# IMM100A register map
Vendor: Infineon; File version: 0.8.0 (Reference Manual v0.8.0)
CPU: CM0 r0p0, little endian, no MPU, no FPU, 2 interrupt priority bits
Registers are 32-bit, read-write, reset 0x0 unless marked. A register's access mark holds for its fields unless they carry their own. Offsets are from the block's base; [hi:lo] are bit positions; {n}, {i} and the like mark numbered series; 'fields as' and 'values as' point back to an identical list.

## PORT1
Base 0x40040100
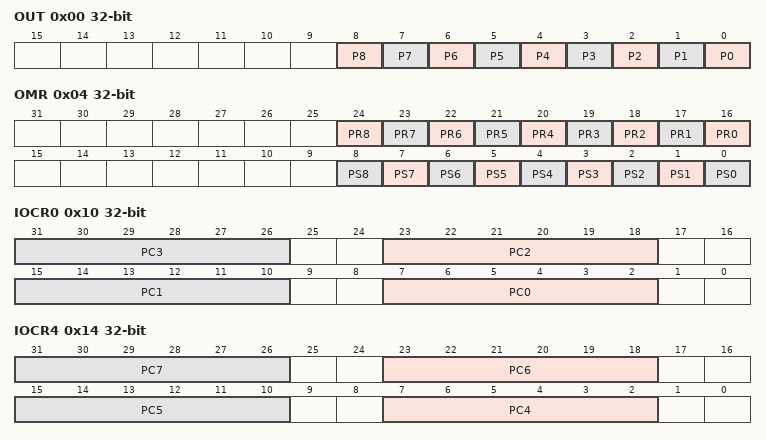
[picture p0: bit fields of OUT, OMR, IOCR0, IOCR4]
0x00 OUT — Port 1 Output Register
  [all] fields
    0=The output level of P1.x is 0; 1=The output level of P1.x is 1
  [8] P8 — Port 1 Output Bit 6
  [7] P7 — Port 1 Output Bit 6
  [n] P{n} (n=0..6) — Port 1 Output Bit {n}
0x04 OMR wo — Port 1 Output Modification Register
  [n+16] PR{n} (n=0..8) — Port 1 Reset Bit {n}
  [n] PS{n} (n=0..8) — Port 1 Set Bit {n}
0x10 IOCR0 — Port 1 Input/Output Control Register 0
  [all] fields
    0=Input - No internal pull device active; 1=Input - Internal pull-down device active; 2=Input - Internal pull-up device active; 3=Input - No internal pull device, Pn_OUTx = input value; 4=Input inverted - No internal pull device active; 5=Input inverted - Internal pull-down device active; 6=Input inverted - Internal pull-up device active; 7=Input inverted - No internal pull device, Pn_OUTx = input value; 32=Output Push-Pull - General-purpose output; {v}=Output Push-Pull - Alternate output function {v-32} (v=33..41); 48=Output Open Drain - General-purpose output; {v}=Output Open Drain - Alternate output function {v-48} (v=49..57)
  [8n+7:8n+2] PC{n} (n=0..3) — Port Control for Port n Pin 0 to 3
0x14 IOCR4 — Port 1 Input/Output Control Register 4
  [all] fields
    values as the fields of IOCR0
  [8n-25:8n-30] PC{n} (n=4..7) — Port Control for Port n Pin 4 to 7
0x18 IOCR8 — Port 1 Input/Output Control Register 8
  [7:2] PC8 — Port Control for Port n Pin 8
    values as the fields of IOCR0
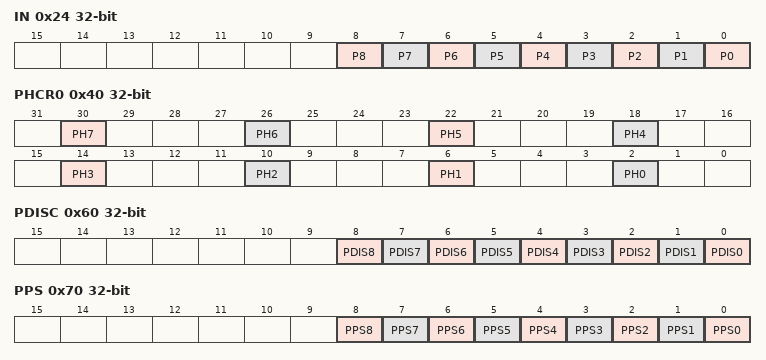
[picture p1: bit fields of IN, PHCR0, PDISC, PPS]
0x24 IN ro (reset mask 0xFFFFF000) — Port 1 Input Register
  [all] fields
    0=The input level of P1.x is 0; 1=The input level of P1.x is 1
  [n] P{n} (n=0..8) — Port 1 Input Bit {n}
0x40 PHCR0 — Port 1 Pad Hysteresis Control Register 0
  [30] PH7 — Pad Hysteresis for P1.7
  [26] PH6 — Pad Hysteresis for P1.6
  [22] PH5 — Pad Hysteresis for P1.5
  [18] PH4 — Pad Hysteresis for P1.4
  [14] PH3 — Pad Hysteresis for P1.3
  [10] PH2 — Pad Hysteresis for P1.2
  [6] PH1 — Pad Hysteresis for P1.1
  [2] PH0 — Pad Hysteresis for P1.0
0x44 PHCR1 — Port 1 Pad Hysteresis Control Register 1
  [2] PH8 — Pad Hysteresis for P1.8
0x60 PDISC ro (reset mask 0xFFFFF000) — Port 1 Pin Function Decision Control Register
  [all] fields
    0=Pad P1.x is enabled; 1=Pad P1.x is disabled
  [n] PDIS{n} (n=0..8) — Pad Disable for Port 1 Pin {n}
0x70 PPS — Port 1 Pin Power Save Register
  [all] fields
    0=Pin Power Save of P1.x is disabled; 1=Pin Power Save of P1.x is enabled
  [n] PPS{n} (n=0..8) — Port 1 Pin Power Save Bit {n}
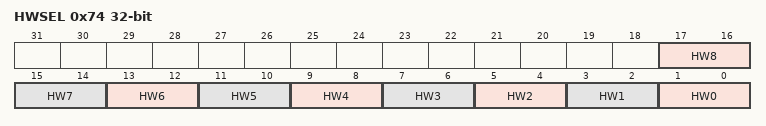
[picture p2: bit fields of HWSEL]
0x74 HWSEL — Port 1 Pin Hardware Select Register
  [all] fields
    0=Software control only; 1=HW0 control path can override the software configuration; 2=HW1 control path can override the software configuration
  [2n+1:2n] HW{n} (n=0..8) — Port 1 Pin Hardware Select Bit {n}

## PORT3
Base 0x40040300
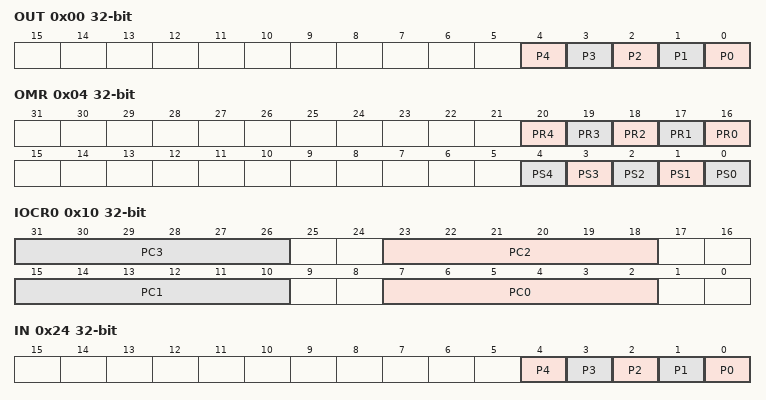
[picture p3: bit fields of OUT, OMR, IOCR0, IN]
0x00 OUT — Port 3 Output Register
  [all] fields
    0=The output level of P3.x is 0; 1=The output level of P3.x is 1
  [n] P{n} (n=0..4) — Port 3 Output Bit {n}
0x04 OMR wo — Port 3 Output Modification Register
  [n+16] PR{n} (n=0..4) — Port 3 Reset Bit {n}
  [n] PS{n} (n=0..4) — Port 3 Set Bit {n}
0x10 IOCR0 — Port 3 Input/Output Control Register 0
  [all] fields
    0=Input - No internal pull device active; 1=Input - Internal pull-down device active; 2=Input - Internal pull-up device active; 3=Input - No internal pull device, Pn_OUTx = input value; 4=Input inverted - No internal pull device active; 5=Input inverted - Internal pull-down device active; 6=Input inverted - Internal pull-up device active; 7=Input inverted - No internal pull device, Pn_OUTx = input value; 32=Output Push-Pull - General-purpose output; {v}=Output Push-Pull - Alternate output function {v-32} (v=33..41); 48=Output Open Drain - General-purpose output; {v}=Output Open Drain - Alternate output function {v-48} (v=49..57)
  [8n+7:8n+2] PC{n} (n=0..3) — Port Control for Port n Pin 0 to 3
0x14 IOCR4 — Port 3 Input/Output Control Register 4
  [7:2] PC4 — Port Control for Port n Pin 4
    values as the fields of IOCR0
0x24 IN ro (reset mask 0xFFFFFF00) — Port 3 Input Register
  [all] fields
    0=The input level of P3.x is 0; 1=The input level of P3.x is 1
  [n] P{n} (n=0..4) — Port 3 Input Bit {n}
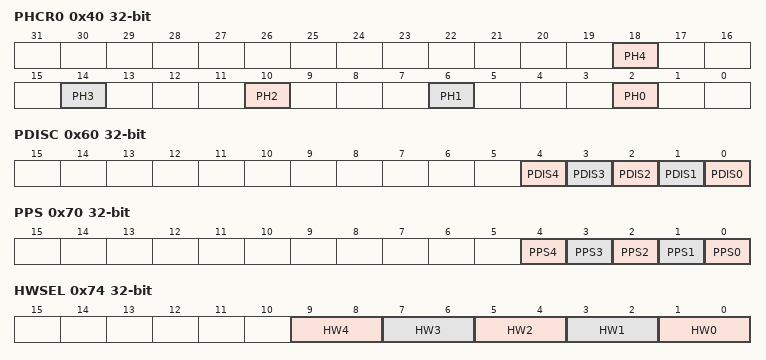
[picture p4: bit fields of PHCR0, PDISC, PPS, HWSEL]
0x40 PHCR0 — Port 3 Pad Hysteresis Control Register 0
  [18] PH4 — Pad Hysteresis for P3.4
  [14] PH3 — Pad Hysteresis for P3.3
  [10] PH2 — Pad Hysteresis for P3.2
  [6] PH1 — Pad Hysteresis for P3.1
  [2] PH0 — Pad Hysteresis for P3.0
0x60 PDISC ro (reset mask 0xFFFFFF00) — Port 3 Pin Function Decision Control Register
  [all] fields
    0=Pad P3.x is enabled; 1=Pad P3.x is disabled
  [n] PDIS{n} (n=0..4) — Pad Disable for Port 3 Pin {n}
0x70 PPS — Port 3 Pin Power Save Register
  [all] fields
    0=Pin Power Save of P3.x is disabled; 1=Pin Power Save of P3.x is enabled
  [n] PPS{n} (n=0..4) — Port 3 Pin Power Save Bit {n}
0x74 HWSEL — Port 3 Pin Hardware Select Register
  [all] fields
    0=Software control only; 1=HW0 control path can override the software configuration; 2=HW1 control path can override the software configuration
  [2n+1:2n] HW{n} (n=0..4) — Port 3 Pin Hardware Select Bit {n}

## PORT4
Base 0x40040400
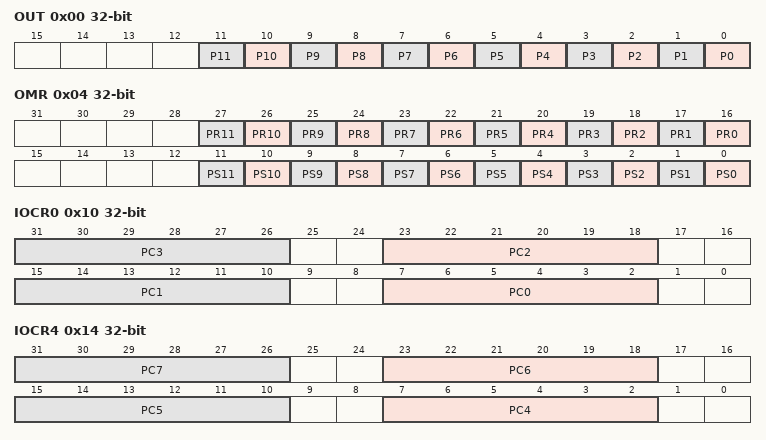
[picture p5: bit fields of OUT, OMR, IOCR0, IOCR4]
0x00 OUT — Port 4 Output Register
  [all] fields
    0=The output level of P4.x is 0; 1=The output level of P4.x is 1
  [n] P{n} (n=0..11) — Port 4 Output Bit {n}
0x04 OMR wo — Port 4 Output Modification Register
  [n+16] PR{n} (n=0..11) — Port 4 Reset Bit {n}
  [n] PS{n} (n=0..11) — Port 4 Set Bit {n}
0x10 IOCR0 — Port 4 Input/Output Control Register 0
  [all] fields
    0=Input - No internal pull device active; 1=Input - Internal pull-down device active; 2=Input - Internal pull-up device active; 3=Input - No internal pull device, Pn_OUTx = input value; 4=Input inverted - No internal pull device active; 5=Input inverted - Internal pull-down device active; 6=Input inverted - Internal pull-up device active; 7=Input inverted - No internal pull device, Pn_OUTx = input value; 32=Output Push-Pull - General-purpose output; {v}=Output Push-Pull - Alternate output function {v-32} (v=33..41); 48=Output Open Drain - General-purpose output; {v}=Output Open Drain - Alternate output function {v-48} (v=49..57)
  [8n+7:8n+2] PC{n} (n=0..3) — Port Control for Port n Pin 0 to 3
0x14 IOCR4 — Port 4 Input/Output Control Register 4
  [all] fields
    values as the fields of IOCR0
  [8n-25:8n-30] PC{n} (n=4..7) — Port Control for Port n Pin 4 to 7
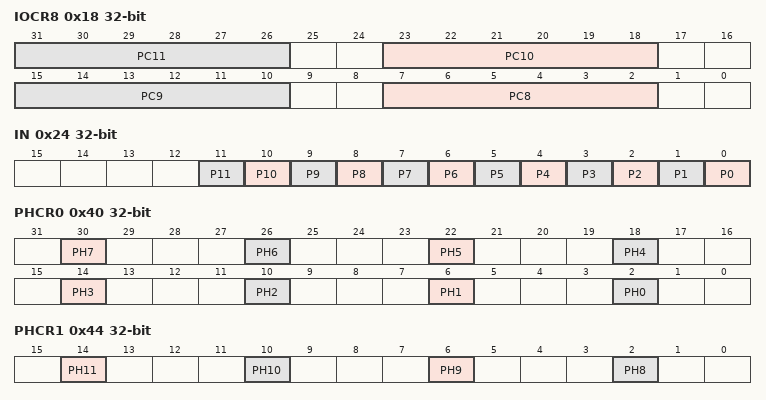
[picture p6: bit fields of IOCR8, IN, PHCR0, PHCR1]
0x18 IOCR8 — Port 4 Input/Output Control Register 8
  [all] fields
    values as the fields of IOCR0
  [8n-57:8n-62] PC{n} (n=8..11) — Port Control for Port n Pin 8 to 11
0x24 IN ro (reset mask 0xFFFFF000) — Port 4 Input Register
  [all] fields
    0=The input level of P4.x is 0; 1=The input level of P4.x is 1
  [n] P{n} (n=0..11) — Port 4 Input Bit {n}
0x40 PHCR0 — Port 4 Pad Hysteresis Control Register 0
  [30] PH7 — Pad Hysteresis for Pn.7
  [26] PH6 — Pad Hysteresis for Pn.6
  [22] PH5 — Pad Hysteresis for Pn.5
  [18] PH4 — Pad Hysteresis for Pn.4
  [14] PH3 — Pad Hysteresis for Pn.3
  [10] PH2 — Pad Hysteresis for Pn.2
  [6] PH1 — Pad Hysteresis for Pn.1
  [2] PH0 — Pad Hysteresis for Pn.0
0x44 PHCR1 — Port 4 Pad Hysteresis Control Register 1
  [14] PH11 — Pad Hysteresis for P4.11
  [10] PH10 — Pad Hysteresis for P4.10
  [6] PH9 — Pad Hysteresis for P4.9
  [2] PH8 — Pad Hysteresis for P4.8
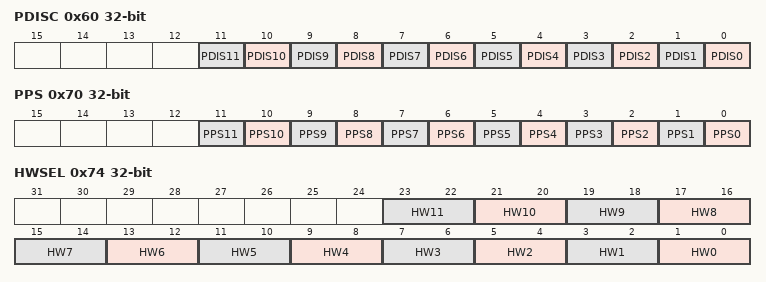
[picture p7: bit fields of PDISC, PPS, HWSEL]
0x60 PDISC ro (reset mask 0xFFFFF000) — Port 4 Pin Function Decision Control Register
  [all] fields
    0=Pad P4.x is enabled; 1=Pad P4.x is disabled
  [n] PDIS{n} (n=0..11) — Pad Disable for Port 4 Pin {n}
0x70 PPS — Port 4 Pin Power Save Register
  [all] fields
    0=Pin Power Save of P4.x is disabled; 1=Pin Power Save of P4.x is enabled
  [n] PPS{n} (n=0..11) — Port 4 Pin Power Save Bit {n}
0x74 HWSEL — Port 4 Pin Hardware Select Register
  [all] fields
    0=Software control only; 1=HW0 control path can override the software configuration; 2=HW1 control path can override the software configuration
  [2n+1:2n] HW{n} (n=0..11) — Port 4 Pin Hardware Select Bit {n}

## iMOTION — iMOTION HAL Data
Base 0x10000F38
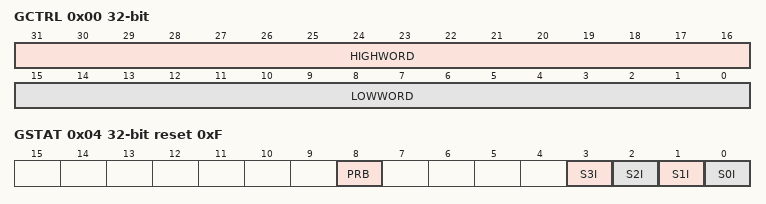
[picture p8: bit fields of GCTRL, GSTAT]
0x00 GCTRL ro — Global Control Register
  [31:16] HIGHWORD, [15:0] LOWWORD
0x04 GSTAT ro reset 0xF — Global Status Register
  [8] PRB — Prescaler Run Bit
    0=Prescaler is stopped; 1=Prescaler is running
  [n] S{n}I (n=0..3) — CC{n+40} IDLE status
    0=Running; 1=Idle
